# ATmega64C1 register map
Vendor: Atmel; File version: 1.0
CPU: other r0p0, little endian, no MPU, no FPU, 4 interrupt priority bits
Registers are 8-bit, read-write, reset 0x0 unless marked. A register's access mark holds for its fields unless they carry their own. Offsets are from the block's base; [hi:lo] are bit positions; {n}, {i} and the like mark numbered series.

## ADC — Analog-to-Digital Converter
Base 0x00000075
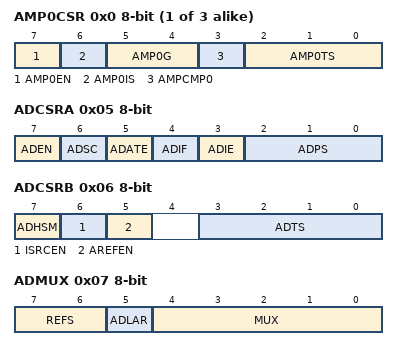
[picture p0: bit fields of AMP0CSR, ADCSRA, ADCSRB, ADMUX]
{0x0+i} AMP{i}CSR (i=0..2)
  [7] AMP{i}EN
  [6] AMP{i}IS
  [5:4] AMP{i}G
  [3] AMPCMP{i} — Amplifier {i} - Comparator {i} Connection
  [2:0] AMP{i}TS
0x03 ADC 16-bit (reset mask 0xFF) — ADC Data Register Bytes
0x05 ADCSRA — The ADC Control and Status register
  [7] ADEN — ADC Enable
  [6] ADSC — ADC Start Conversion
  [5] ADATE — ADC Auto Trigger Enable
  [4] ADIF — ADC Interrupt Flag
  [3] ADIE — ADC Interrupt Enable
  [2:0] ADPS — ADC Prescaler Select Bits
0x06 ADCSRB — ADC Control and Status Register B
  [7] ADHSM — ADC High Speed Mode
  [6] ISRCEN — Current Source Enable
  [5] AREFEN — Analog Reference pin Enable
  [3:0] ADTS — ADC Auto Trigger Sources
    0=Free Running mode; 1=Analog Comparator; 2=External Interrupt Request 0; 3=Timer/Counter0 Compare Match A; 4=Timer/Counter0 Overflow; 5=Timer/Counter1 Compare Match B; 6=Timer/Counter1 Overflow; 7=Timer/Counter1 Capture Event; 8=PSC0ASY Event; 9=PSC1ASY Event; 10=PSC2ASY Event; 11=Analog comparator 1; 12=Analog comparator 2
0x07 ADMUX — The ADC multiplexer Selection Register
  [7:6] REFS — Reference Selection Bits
    0=AREF, Internal Vref turned off; 1=AVCC with external capacitor at AREF pin; 3=Internal 2.56V Voltage Reference with external capacitor at AREF pin
  [5] ADLAR — Left Adjust Result
  [4:0] MUX — Analog Channel and Gain Selection Bits
    {v}=ADC{v} (ADC input pin {v}) (v=0..10); 11=TEMPSENSE (Temperature sensor); 12=VCC4 (Internal VCC / 4); 13=ISRC (Current source); 14=AMP0 (Analog Differential Amplifier 0); 15=AMP1 (Analog Differential Amplifier 1); 16=AMP2 (Analog Differential Amplifier 2); 17=BNDGAP (Bandgap); 18=GND (0V (GND))
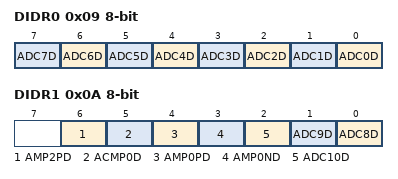
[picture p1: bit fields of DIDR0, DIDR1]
0x09 DIDR0 — Digital Input Disable Register 0
  [n] ADC{n}D (n=0..7) — ADC{n} Digital input Disable
0x0A DIDR1 — Digital Input Disable Register 0
  [6] AMP2PD — AMP2P Pin Digital input Disable
  [5] ACMP0D — ACMP0 Pin Digital input Disable
  [4] AMP0PD — AMP0P Pin Digital input Disable
  [3] AMP0ND — AMP0N Pin Digital input Disable
  [2] ADC10D — ADC10 Pin Digital input Disable
  [1] ADC9D — ADC9 Pin Digital input Disable
  [0] ADC8D — ADC8 Pin Digital input Disable

## CAN — Controller Area Network
Base 0x000000D8
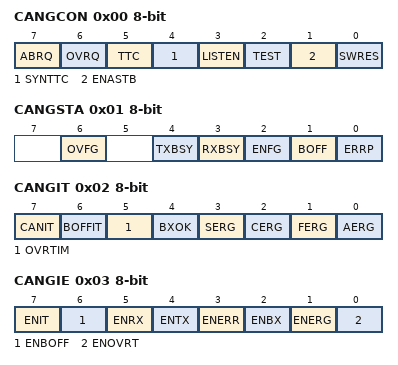
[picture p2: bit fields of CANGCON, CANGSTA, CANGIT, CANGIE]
0x00 CANGCON — CAN General Control Register
  [7] ABRQ — Abort Request
  [6] OVRQ — Overload Frame Request
  [5] TTC — Time Trigger Communication
  [4] SYNTTC — Synchronization of TTC
  [3] LISTEN — Listening Mode
  [2] TEST — Test Mode
  [1] ENASTB — Enable / Standby
  [0] SWRES — Software Reset Request
0x01 CANGSTA — CAN General Status Register
  [6] OVFG — Overload Frame Flag
  [4] TXBSY — Transmitter Busy
  [3] RXBSY — Receiver Busy
  [2] ENFG — Enable Flag
  [1] BOFF — Bus Off Mode
  [0] ERRP — Error Passive Mode
0x02 CANGIT — CAN General Interrupt Register Flags
  [7] CANIT — General Interrupt Flag
  [6] BOFFIT — Bus Off Interrupt Flag
  [5] OVRTIM — Overrun CAN Timer Flag
  [4] BXOK — Burst Receive Interrupt Flag
  [3] SERG — Stuff Error General Flag
  [2] CERG — CRC Error General Flag
  [1] FERG — Form Error General Flag
  [0] AERG — Ackknowledgement Error General Flag
0x03 CANGIE — CAN General Interrupt Enable Register
  [7] ENIT — Enable all Interrupts
  [6] ENBOFF — Enable Bus Off Interrupt
  [5] ENRX — Enable Receive Interrupt
  [4] ENTX — Enable Transmitt Interrupt
  [3] ENERR — Enable MOb Error Interrupt
  [2] ENBX — Enable Burst Receive Interrupt
  [1] ENERG — Enable General Error Interrupt
  [0] ENOVRT — Enable CAN Timer Overrun Interrupt
0x04 CANEN2 — Enable MOb Register 2
  [5:0] ENMOB — Enable MObs
0x05 CANEN1 — Enable MOb Register 1(empty)
0x06 CANIE2 — Enable Interrupt MOb Register 2
  [5:0] IEMOB — Interrupt Enable MObs
0x07 CANIE1 — Enable Interrupt MOb Register 1 (empty)
0x08 CANSIT2 — CAN Status Interrupt MOb Register 2
  [5:0] SIT — Status of Interrupt MObs
0x09 CANSIT1 — CAN Status Interrupt MOb Register 1 (empty)
0x0A CANBT1 — CAN Bit Timing Register 1
  [6:1] BRP — Baud Rate Prescaler bits
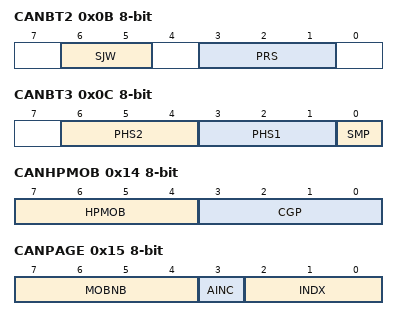
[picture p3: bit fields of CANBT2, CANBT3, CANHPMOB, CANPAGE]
0x0B CANBT2 — CAN Bit Timing Register 2
  [6:5] SJW — Re-Sync Jump Width bits
  [3:1] PRS — Propagation Time Segment bits
0x0C CANBT3 — CAN Bit Timing Register 3
  [6:4] PHS2 — Phase Segment 2 bits
  [3:1] PHS1 — Phase Segment 1 bits
  [0] SMP — Sample Type
0x0D CANTCON — Timer Control Register
0x0E CANTIML — Timer Register Low
0x0F CANTIMH — Timer Register High
0x10 CANTTCL — TTC Timer Register Low
0x11 CANTTCH — TTC Timer Register High
0x12 CANTEC — Transmit Error Counter Register
0x13 CANREC — Receive Error Counter Register
0x14 CANHPMOB — Highest Priority MOb Register
  [7:4] HPMOB — Highest Priority MOb Number bits
  [3:0] CGP — CAN General Purpose bits
0x15 CANPAGE — Page MOb Register
  [7:4] MOBNB — MOb Number bits
  [3] AINC — MOb Data Buffer Auto Increment (Active Low)
  [2:0] INDX — Data Buffer Index bits
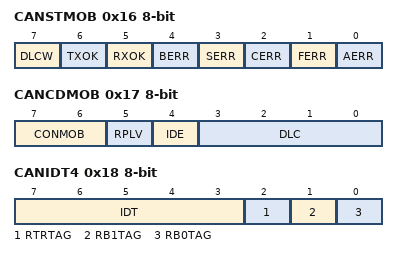
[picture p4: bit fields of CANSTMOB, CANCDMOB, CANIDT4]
0x16 CANSTMOB — MOb Status Register
  [7] DLCW — Data Length Code Warning on MOb
  [6] TXOK — Transmit OK on MOb
  [5] RXOK — Receive OK on MOb
  [4] BERR — Bit Error on MOb
  [3] SERR — Stuff Error on MOb
  [2] CERR — CRC Error on MOb
  [1] FERR — Form Error on MOb
  [0] AERR — Ackknowledgement Error on MOb
0x17 CANCDMOB — MOb Control and DLC Register
  [7:6] CONMOB — MOb Config bits
  [5] RPLV — Reply Valid
  [4] IDE — Identifier Extension
  [3:0] DLC — Data Length Code bits
0x18 CANIDT4 — Identifier Tag Register 4
  [7:3] IDT, [2] RTRTAG, [1] RB1TAG, [0] RB0TAG
0x19 CANIDT3 — Identifier Tag Register 3
0x1A CANIDT2 — Identifier Tag Register 2
0x1B CANIDT1 — Identifier Tag Register 1
0x1C CANIDM4 — Identifier Mask Register 4
0x1D CANIDM3 — Identifier Mask Register 3
0x1E CANIDM2 — Identifier Mask Register 2
0x1F CANIDM1 — Identifier Mask Register 1
0x20 CANSTML — Time Stamp Register Low
0x21 CANSTMH — Time Stamp Register High
0x22 CANMSG — Message Data Register
